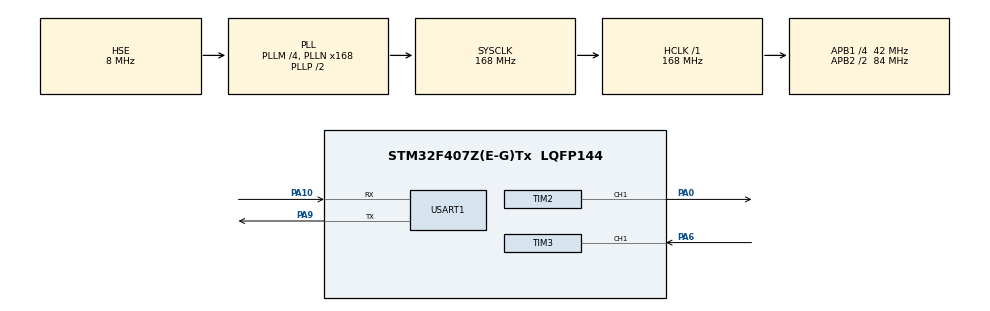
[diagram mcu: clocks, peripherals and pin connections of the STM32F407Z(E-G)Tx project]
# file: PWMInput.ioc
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Mcu.Family=STM32F4
Mcu.Name=STM32F407Z(E-G)Tx
Mcu.Package=LQFP144
NVIC.PriorityGroup=NVIC_PRIORITYGROUP_4
NVIC.TIM3_IRQn=true\:0\:0\:false\:false\:true\:true\:true
PA0-WKUP.Signal=S_TIM2_CH1_ETR
PA10.Mode=Asynchronous
PA10.Signal=USART1_RX
PA6.Signal=S_TIM3_CH1
PA9.Mode=Asynchronous
PA9.Signal=USART1_TX
PC14-OSC32_IN.Mode=LSE-External-Oscillator
PC14-OSC32_IN.Signal=RCC_OSC32_IN
PC15-OSC32_OUT.Mode=LSE-External-Oscillator
PC15-OSC32_OUT.Signal=RCC_OSC32_OUT
PH0-OSC_IN.Mode=HSE-External-Oscillator
PH0-OSC_IN.Signal=RCC_OSC_IN
PH1-OSC_OUT.Mode=HSE-External-Oscillator
PH1-OSC_OUT.Signal=RCC_OSC_OUT
ProjectManager.HeapSize=0x200
ProjectManager.StackSize=0x400
ProjectManager.TargetToolchain=MDK-ARM V5.32
RCC.48MHZClocksFreq_Value=84000000
RCC.AHBFreq_Value=168000000
RCC.APB1CLKDivider=RCC_HCLK_DIV4
RCC.APB1Freq_Value=42000000
RCC.APB1TimFreq_Value=84000000
RCC.APB2CLKDivider=RCC_HCLK_DIV2
RCC.APB2Freq_Value=84000000
RCC.APB2TimFreq_Value=168000000
RCC.CortexFreq_Value=168000000
RCC.HCLKFreq_Value=168000000
RCC.HSE_VALUE=8000000
RCC.HSI_VALUE=16000000
RCC.PLLM=4
RCC.PLLN=168
RCC.PLLSourceVirtual=RCC_PLLSOURCE_HSE
RCC.SYSCLKFreq_VALUE=168000000
RCC.SYSCLKSource=RCC_SYSCLKSOURCE_PLLCLK
RCC.VCOOutputFreq_Value=336000000
SH.S_TIM2_CH1_ETR.0=TIM2_CH1,PWM Generation1 CH1
SH.S_TIM3_CH1.0=TIM3_CH1,TriggerSource_TI1FP1
SH.S_TIM3_CH1.1=TIM3_CH1,Input_Capture1_from_TI1
TIM2.Channel-PWM\ Generation1\ CH1=TIM_CHANNEL_1
TIM2.Period=10000-1
TIM2.Prescaler=84-1
TIM2.Pulse-PWM\ Generation1\ CH1=5000
TIM3.AutoReloadPreload=TIM_AUTORELOAD_PRELOAD_ENABLE
TIM3.Channel-Input_Capture1_from_TI1=TIM_CHANNEL_1
TIM3.Channel-Input_Capture2_from_TI1_63=TIM_CHANNEL_2
TIM3.ICPolarity_CH2=TIM_INPUTCHANNELPOLARITY_FALLING
TIM3.Prescaler=84-1
USART1.VirtualMode=VM_ASYNC
VP_TIM2_VS_ClockSourceINT.Mode=Internal
VP_TIM3_VS_ClockSourceINT.Mode=Internal
VP_TIM3_VS_ControllerModeReset.Mode=Reset Mode
VP_TIM3_VS_indirect_ch1.Mode=Input_Capture2_from_TI1_63
board=custom

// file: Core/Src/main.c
/* USER CODE BEGIN Header */
/**
  ******************************************************************************
  * @file           : main.c
  * @brief          : Main program body
  ******************************************************************************
  * @attention
  *
  * <h2><center>&copy; Copyright (c) 2021 STMicroelectronics.
  * All rights reserved.</center></h2>
  *
  * This software component is licensed by ST under BSD 3-Clause license,
  * the "License"; You may not use this file except in compliance with the
  * License. You may obtain a copy of the License at:
  *                        opensource.org/licenses/BSD-3-Clause
  *
  ******************************************************************************
  */
/* USER CODE END Header */
#include "main.h"
#include "tim.h"
#include "usart.h"
#include "gpio.h"

void SystemClock_Config(void);

int main(void)
{

  /* MCU Configuration--------------------------------------------------------*/

  /* Reset of all peripherals, Initializes the Flash interface and the Systick. */
  HAL_Init();

  /* Configure the system clock */
  SystemClock_Config();

  /* Initialize all configured peripherals */
  MX_GPIO_Init();
  MX_TIM2_Init();
  MX_TIM3_Init();
  MX_USART1_UART_Init();
  /* USER CODE BEGIN 2 */
	/// 使能捕获/比较2中断请求
	HAL_TIM_IC_Start_IT(&htim3,TIM_CHANNEL_1);
	HAL_TIM_IC_Start_IT(&htim3,TIM_CHANNEL_2);

	/// 开始输出PWM
	HAL_TIM_PWM_Start(&htim2,TIM_CHANNEL_1);
  /* USER CODE END 2 */

  /* Infinite loop */
  while (1)
  {

    /* USER CODE BEGIN 3 */
		printf("IC1Value=%d\r\n",IC1Value);
		printf("IC2Value=%d\r\n",IC2Value);
		printf("占空比:%f\r\n",DutyCycle);
		printf("频率:%f\r\n",Frequency);

		HAL_Delay(500);

  }
  /* USER CODE END 3 */
}

void SystemClock_Config(void)
{
  RCC_OscInitTypeDef RCC_OscInitStruct = {0};
  RCC_ClkInitTypeDef RCC_ClkInitStruct = {0};

  /** Configure the main internal regulator output voltage
  */
  __HAL_RCC_PWR_CLK_ENABLE();
  __HAL_PWR_VOLTAGESCALING_CONFIG(PWR_REGULATOR_VOLTAGE_SCALE1);
  /** Initializes the RCC Oscillators according to the specified parameters
  * in the RCC_OscInitTypeDef structure.
  */
  RCC_OscInitStruct.OscillatorType = RCC_OSCILLATORTYPE_HSE;
  RCC_OscInitStruct.HSEState = RCC_HSE_ON;
  RCC_OscInitStruct.PLL.PLLState = RCC_PLL_ON;
  RCC_OscInitStruct.PLL.PLLSource = RCC_PLLSOURCE_HSE;
  RCC_OscInitStruct.PLL.PLLM = 4;
  RCC_OscInitStruct.PLL.PLLN = 168;
  RCC_OscInitStruct.PLL.PLLP = RCC_PLLP_DIV2;
  RCC_OscInitStruct.PLL.PLLQ = 4;
  if (HAL_RCC_OscConfig(&RCC_OscInitStruct) != HAL_OK)
  {
    Error_Handler();
  }
  /** Initializes the CPU, AHB and APB buses clocks
  */
  RCC_ClkInitStruct.ClockType = RCC_CLOCKTYPE_HCLK|RCC_CLOCKTYPE_SYSCLK
                              |RCC_CLOCKTYPE_PCLK1|RCC_CLOCKTYPE_PCLK2;
  RCC_ClkInitStruct.SYSCLKSource = RCC_SYSCLKSOURCE_PLLCLK;
  RCC_ClkInitStruct.AHBCLKDivider = RCC_SYSCLK_DIV1;
  RCC_ClkInitStruct.APB1CLKDivider = RCC_HCLK_DIV4;
  RCC_ClkInitStruct.APB2CLKDivider = RCC_HCLK_DIV2;

  if (HAL_RCC_ClockConfig(&RCC_ClkInitStruct, FLASH_LATENCY_5) != HAL_OK)
  {
    Error_Handler();
  }
}

void Error_Handler(void)
{
  __disable_irq();
  while (1)
  {
  }
}

/************************ (C) COPYRIGHT STMicroelectronics *****END OF FILE****/
